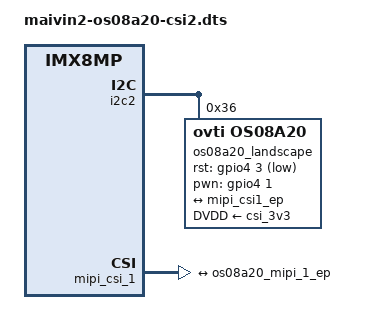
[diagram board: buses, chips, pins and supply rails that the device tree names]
// SPDX-License-Identifier: AGPL-3.0
/*
 * Copyright 2023 Au-Zone Technologies
 */

// OmniVision OS08A20 4K Camera on CSI2 "Landscape" for Maivin 2

/dts-v1/;
/plugin/;

#include <dt-bindings/clock/imx8mp-clock.h>
#include <dt-bindings/gpio/gpio.h>

#include "imx8mp-pinfunc.h"

/ {
	compatible = "toradex,verdin-imx8mp";
};

/* Verdin I2C_2_CSI */
&i2c2 {
	#address-cells = <1>;
	#size-cells = <0>;
	status = "okay";

	os08a20_landscape: os08a20_mipi@36 {
		compatible = "ovti,os08a20";
		reg = <0x36>;
		pinctrl-names = "default";
		pinctrl-0 = <&pinctrl_csi2_control>;
		DVDD-supply = <&csi_3v3>;
		clocks = <&clk_dummy>;
		clock-names = "csi_mclk";
		mclk = <24000000>;
		mclk_source = <0>;
		csi_id = <1>;
		status = "okay";

		rst-gpios = <&gpio4 3 GPIO_ACTIVE_LOW>;
		pwn-gpios = <&gpio4 1 GPIO_ACTIVE_HIGH>;

		port {
			os08a20_mipi_1_ep: endpoint {
				data-lanes = <1 2 3 4>;
				clock-lanes = <0>;
				max-pixel-frequency = /bits/ 64 <500000000>;
				remote-endpoint = <&mipi_csi1_ep>;
			};
		};
	};
};

&mipi_csi_1 {
	#address-cells = <1>;
	#size-cells = <0>;
	clock-frequency = <500000000>;
	assigned-clock-parents = <&clk IMX8MP_SYS_PLL2_1000M>;
	assigned-clock-rates = <500000000>;
	status = "okay";

	port@1 {
		reg = <1>;
		mipi_csi1_ep: endpoint {
			remote-endpoint = <&os08a20_mipi_1_ep>;
			data-lanes = <4>;
			csis-hs-settle = <16>;
			csis-clk-settle = <2>;
			csis-wclk;
		};
	};
};
